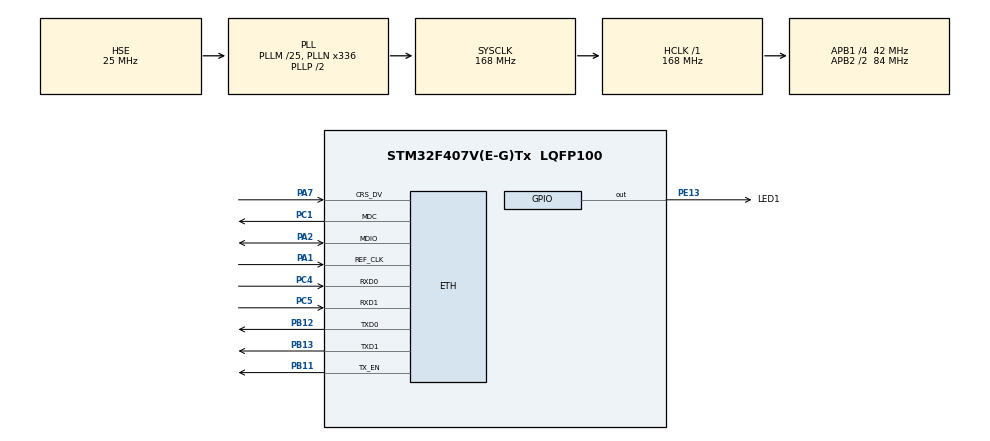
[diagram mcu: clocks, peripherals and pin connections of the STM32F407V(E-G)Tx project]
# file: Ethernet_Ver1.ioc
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ETH.MediaInterface=HAL_ETH_RMII_MODE
LWIP.BSP.number=1
LWIP.GATEWAY_ADDRESS=192.168.165.254
LWIP.IP_ADDRESS=192.168.165.041
LWIP.LWIP_DHCP=0
LWIP.LWIP_HTTPD=1
LWIP.LWIP_HTTPD_CGI=1
LWIP.LWIP_HTTPD_SSI=1
LWIP.MEM_SIZE=1024*10
LWIP.NETMASK_ADDRESS=255.255.255.000
LWIP.Version=v2.1.2_Cube
LWIP0.BSP.STBoard=false
LWIP0.BSP.api=BSP_COMPONENT_DRIVER
LWIP0.BSP.component=DP83848
LWIP0.BSP.instance=DP83848
LWIP0.BSP.name=Driver_PHY
LWIP0.BSP.semaphore=S_DP83848
LWIP0.BSP.solution=DP83848
Mcu.Family=STM32F4
Mcu.Name=STM32F407V(E-G)Tx
Mcu.Package=LQFP100
NVIC.ETH_IRQn=true\:0\:0\:false\:false\:true\:true\:true\:true
NVIC.PriorityGroup=NVIC_PRIORITYGROUP_4
NVIC.TIM1_UP_TIM10_IRQn=true\:0\:0\:false\:false\:true\:true\:true\:true
PA1.Mode=RMII
PA1.Signal=ETH_REF_CLK
PA13.Mode=Serial_Wire
PA13.Signal=SYS_JTMS-SWDIO
PA14.Mode=Serial_Wire
PA14.Signal=SYS_JTCK-SWCLK
PA2.Mode=RMII
PA2.Signal=ETH_MDIO
PA7.Mode=RMII
PA7.Signal=ETH_CRS_DV
PB11.Mode=RMII
PB11.Signal=ETH_TX_EN
PB12.Mode=RMII
PB12.Signal=ETH_TXD0
PB13.Mode=RMII
PB13.Signal=ETH_TXD1
PC1.Mode=RMII
PC1.Signal=ETH_MDC
PC4.Mode=RMII
PC4.Signal=ETH_RXD0
PC5.Mode=RMII
PC5.Signal=ETH_RXD1
PE13.GPIO_Label=LED1
PE13.Signal=GPIO_Output
PH0-OSC_IN.Mode=HSE-External-Oscillator
PH0-OSC_IN.Signal=RCC_OSC_IN
PH1-OSC_OUT.Mode=HSE-External-Oscillator
PH1-OSC_OUT.Signal=RCC_OSC_OUT
ProjectManager.HeapSize=0x200
ProjectManager.StackSize=0x400
ProjectManager.TargetToolchain=STM32CubeIDE
RCC.48MHZClocksFreq_Value=48000000
RCC.AHBFreq_Value=168000000
RCC.APB1CLKDivider=RCC_HCLK_DIV4
RCC.APB1Freq_Value=42000000
RCC.APB1TimFreq_Value=84000000
RCC.APB2CLKDivider=RCC_HCLK_DIV2
RCC.APB2Freq_Value=84000000
RCC.APB2TimFreq_Value=168000000
RCC.CortexFreq_Value=168000000
RCC.HCLKFreq_Value=168000000
RCC.HSE_VALUE=25000000
RCC.HSI_VALUE=16000000
RCC.LSE_VALUE=32768
RCC.PLLM=25
RCC.PLLN=336
RCC.PLLQ=7
RCC.PLLSourceVirtual=RCC_PLLSOURCE_HSE
RCC.SYSCLKFreq_VALUE=168000000
RCC.SYSCLKSource=RCC_SYSCLKSOURCE_PLLCLK
RCC.VCOOutputFreq_Value=336000000
TIM1.AutoReloadPreload=TIM_AUTORELOAD_PRELOAD_ENABLE
TIM1.Period=10000-1
TIM1.Prescaler=8400-1
VP_LWIP_VS_Enabled.Mode=Enabled
VP_TIM1_VS_ClockSourceINT.Mode=Internal
board=custom

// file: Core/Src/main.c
/* USER CODE BEGIN Header */
/**
 ******************************************************************************
 * @file           : main.c
 * @brief          : Main program body
 ******************************************************************************
 * @attention
 *
 * Copyright (c) 2026 STMicroelectronics.
 * All rights reserved.
 *
 * This software is licensed under terms that can be found in the LICENSE file
 * in the root directory of this software component.
 * If no LICENSE file comes with this software, it is provided AS-IS.
 *
 ******************************************************************************
 */
/* USER CODE END Header */
#include "main.h"
#include "lwip.h"

/* USER CODE BEGIN Includes */
#include "lwip/apps/httpd.h"
//#include "tcpClientRAW.h"
//#include "tcpServerRAW.h"
//#include "udpServerRAW.h"
#include "http_ssi.h"
/* USER CODE END Includes */

TIM_HandleTypeDef htim1;

void SystemClock_Config(void);
static void MX_GPIO_Init(void);
static void MX_TIM1_Init(void);

/* USER CODE BEGIN 0 */
extern struct netif gnetif;
// struct pbuf gbuf;
/* USER CODE END 0 */

int main(void)
{

  /* MCU Configuration--------------------------------------------------------*/

  /* Reset of all peripherals, Initializes the Flash interface and the Systick. */
  HAL_Init();

  /* Configure the system clock */
  SystemClock_Config();

  /* USER CODE BEGIN SysInit */
  HAL_Delay(3000);
  /* USER CODE END SysInit */

  /* Initialize all configured peripherals */
  MX_GPIO_Init();
  MX_LWIP_Init();
  MX_TIM1_Init();
  /* USER CODE BEGIN 2 */

  //  udpServer_init();
  //  udpClient_connect();
  //  tcp_server_init();
  //  tcp_client_init();
  //  HAL_TIM_Base_Start_IT(&htim1);

//  httpd_init();
  http_server_init();
  /* USER CODE END 2 */

  /* Infinite loop */
  /* USER CODE BEGIN WHILE */
  while (1) {
    //	  HAL_GPIO_TogglePin(GPIOD, GPIO_PIN_9);
    //	  ethernetif_input(&gnetif);
    //	  sys_check_timeouts();
    MX_LWIP_Process();
    //	  tcp_client_reconnect_process();
    /* USER CODE END WHILE */

  }
}

void SystemClock_Config(void)
{
  RCC_OscInitTypeDef RCC_OscInitStruct = {0};
  RCC_ClkInitTypeDef RCC_ClkInitStruct = {0};

  /** Configure the main internal regulator output voltage
  */
  __HAL_RCC_PWR_CLK_ENABLE();
  __HAL_PWR_VOLTAGESCALING_CONFIG(PWR_REGULATOR_VOLTAGE_SCALE1);

  /** Initializes the RCC Oscillators according to the specified parameters
  * in the RCC_OscInitTypeDef structure.
  */
  RCC_OscInitStruct.OscillatorType = RCC_OSCILLATORTYPE_HSE;
  RCC_OscInitStruct.HSEState = RCC_HSE_ON;
  RCC_OscInitStruct.PLL.PLLState = RCC_PLL_ON;
  RCC_OscInitStruct.PLL.PLLSource = RCC_PLLSOURCE_HSE;
  RCC_OscInitStruct.PLL.PLLM = 25;
  RCC_OscInitStruct.PLL.PLLN = 336;
  RCC_OscInitStruct.PLL.PLLP = RCC_PLLP_DIV2;
  RCC_OscInitStruct.PLL.PLLQ = 7;
  if (HAL_RCC_OscConfig(&RCC_OscInitStruct) != HAL_OK)
  {
    Error_Handler();
  }

  /** Initializes the CPU, AHB and APB buses clocks
  */
  RCC_ClkInitStruct.ClockType = RCC_CLOCKTYPE_HCLK|RCC_CLOCKTYPE_SYSCLK
                              |RCC_CLOCKTYPE_PCLK1|RCC_CLOCKTYPE_PCLK2;
  RCC_ClkInitStruct.SYSCLKSource = RCC_SYSCLKSOURCE_PLLCLK;
  RCC_ClkInitStruct.AHBCLKDivider = RCC_SYSCLK_DIV1;
  RCC_ClkInitStruct.APB1CLKDivider = RCC_HCLK_DIV4;
  RCC_ClkInitStruct.APB2CLKDivider = RCC_HCLK_DIV2;

  if (HAL_RCC_ClockConfig(&RCC_ClkInitStruct, FLASH_LATENCY_5) != HAL_OK)
  {
    Error_Handler();
  }
}

static void MX_TIM1_Init(void)
{

  TIM_ClockConfigTypeDef sClockSourceConfig = {0};
  TIM_MasterConfigTypeDef sMasterConfig = {0};

  htim1.Instance = TIM1;
  htim1.Init.Prescaler = 8400-1;
  htim1.Init.CounterMode = TIM_COUNTERMODE_UP;
  htim1.Init.Period = 10000-1;
  htim1.Init.ClockDivision = TIM_CLOCKDIVISION_DIV1;
  htim1.Init.RepetitionCounter = 0;
  htim1.Init.AutoReloadPreload = TIM_AUTORELOAD_PRELOAD_ENABLE;
  if (HAL_TIM_Base_Init(&htim1) != HAL_OK)
  {
    Error_Handler();
  }
  sClockSourceConfig.ClockSource = TIM_CLOCKSOURCE_INTERNAL;
  if (HAL_TIM_ConfigClockSource(&htim1, &sClockSourceConfig) != HAL_OK)
  {
    Error_Handler();
  }
  sMasterConfig.MasterOutputTrigger = TIM_TRGO_RESET;
  sMasterConfig.MasterSlaveMode = TIM_MASTERSLAVEMODE_DISABLE;
  if (HAL_TIMEx_MasterConfigSynchronization(&htim1, &sMasterConfig) != HAL_OK)
  {
    Error_Handler();
  }

}

static void MX_GPIO_Init(void)
{
  GPIO_InitTypeDef GPIO_InitStruct = {0};

  /* GPIO Ports Clock Enable */
  __HAL_RCC_GPIOH_CLK_ENABLE();
  __HAL_RCC_GPIOC_CLK_ENABLE();
  __HAL_RCC_GPIOA_CLK_ENABLE();
  __HAL_RCC_GPIOE_CLK_ENABLE();
  __HAL_RCC_GPIOB_CLK_ENABLE();

  /*Configure GPIO pin Output Level */
  HAL_GPIO_WritePin(LED1_GPIO_Port, LED1_Pin, GPIO_PIN_RESET);

  /*Configure GPIO pin : LED1_Pin */
  GPIO_InitStruct.Pin = LED1_Pin;
  GPIO_InitStruct.Mode = GPIO_MODE_OUTPUT_PP;
  GPIO_InitStruct.Pull = GPIO_NOPULL;
  GPIO_InitStruct.Speed = GPIO_SPEED_FREQ_LOW;
  HAL_GPIO_Init(LED1_GPIO_Port, &GPIO_InitStruct);

}

void Error_Handler(void)
{
  __disable_irq();
  while (1) {
  }
}

#ifdef  USE_FULL_ASSERT
/**
  * @brief  Reports the name of the source file and the source line number
  *         where the assert_param error has occurred.
  * @param  file: pointer to the source file name
  * @param  line: assert_param error line source number
  * @retval None
  */
void assert_failed(uint8_t *file, uint32_t line)
{
  /* USER CODE BEGIN 6 */
  /* User can add his own implementation to report the file name and line
     number, ex: printf("Wrong parameters value: file %s on line %d\r\n", file,
     line) */
  /* USER CODE END 6 */
}
#endif /* USE_FULL_ASSERT */
